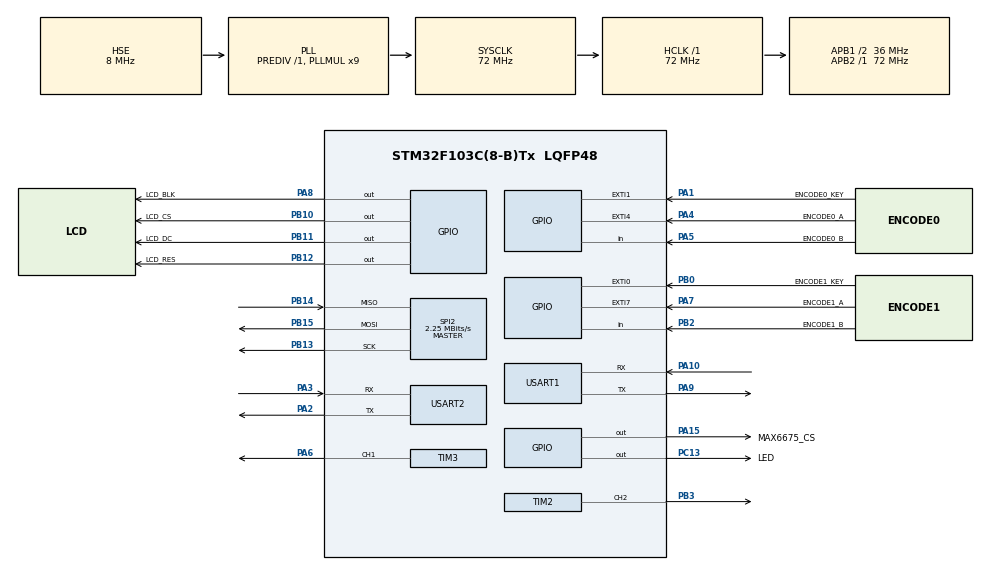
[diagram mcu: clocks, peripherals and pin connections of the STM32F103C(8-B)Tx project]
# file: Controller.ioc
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Dma.Request0=SPI2_RX
Dma.Request1=SPI2_TX
Dma.Request2=USART2_RX
Dma.Request3=USART2_TX
Dma.SPI2_RX.0.Direction=DMA_PERIPH_TO_MEMORY
Dma.SPI2_RX.0.Instance=DMA1_Channel4
Dma.SPI2_RX.0.MemDataAlignment=DMA_MDATAALIGN_BYTE
Dma.SPI2_RX.0.MemInc=DMA_MINC_ENABLE
Dma.SPI2_RX.0.Mode=DMA_NORMAL
Dma.SPI2_RX.0.PeriphDataAlignment=DMA_PDATAALIGN_BYTE
Dma.SPI2_RX.0.PeriphInc=DMA_PINC_DISABLE
Dma.SPI2_RX.0.Priority=DMA_PRIORITY_LOW
Dma.SPI2_TX.1.Direction=DMA_MEMORY_TO_PERIPH
Dma.SPI2_TX.1.Instance=DMA1_Channel5
Dma.SPI2_TX.1.MemDataAlignment=DMA_MDATAALIGN_BYTE
Dma.SPI2_TX.1.MemInc=DMA_MINC_ENABLE
Dma.SPI2_TX.1.Mode=DMA_NORMAL
Dma.SPI2_TX.1.PeriphDataAlignment=DMA_PDATAALIGN_BYTE
Dma.SPI2_TX.1.PeriphInc=DMA_PINC_DISABLE
Dma.SPI2_TX.1.Priority=DMA_PRIORITY_LOW
Dma.USART2_RX.2.Direction=DMA_PERIPH_TO_MEMORY
Dma.USART2_RX.2.Instance=DMA1_Channel6
Dma.USART2_RX.2.MemDataAlignment=DMA_MDATAALIGN_BYTE
Dma.USART2_RX.2.MemInc=DMA_MINC_ENABLE
Dma.USART2_RX.2.Mode=DMA_NORMAL
Dma.USART2_RX.2.PeriphDataAlignment=DMA_PDATAALIGN_BYTE
Dma.USART2_RX.2.PeriphInc=DMA_PINC_DISABLE
Dma.USART2_RX.2.Priority=DMA_PRIORITY_LOW
Dma.USART2_TX.3.Direction=DMA_MEMORY_TO_PERIPH
Dma.USART2_TX.3.Instance=DMA1_Channel7
Dma.USART2_TX.3.MemDataAlignment=DMA_MDATAALIGN_BYTE
Dma.USART2_TX.3.MemInc=DMA_MINC_ENABLE
Dma.USART2_TX.3.Mode=DMA_NORMAL
Dma.USART2_TX.3.PeriphDataAlignment=DMA_PDATAALIGN_BYTE
Dma.USART2_TX.3.PeriphInc=DMA_PINC_DISABLE
Dma.USART2_TX.3.Priority=DMA_PRIORITY_LOW
Mcu.Family=STM32F1
Mcu.Name=STM32F103C(8-B)Tx
Mcu.Package=LQFP48
NVIC.DMA1_Channel4_IRQn=true\:0\:0\:false\:false\:true\:false\:true\:true
NVIC.DMA1_Channel5_IRQn=true\:0\:0\:false\:false\:true\:false\:true\:true
NVIC.DMA1_Channel6_IRQn=true\:0\:0\:false\:false\:true\:false\:true\:true
NVIC.DMA1_Channel7_IRQn=true\:0\:0\:false\:false\:true\:false\:true\:true
NVIC.EXTI0_IRQn=true\:0\:0\:false\:false\:true\:true\:true\:true
NVIC.EXTI1_IRQn=true\:0\:0\:false\:false\:true\:true\:true\:true
NVIC.EXTI4_IRQn=true\:0\:0\:false\:false\:true\:true\:true\:true
NVIC.PriorityGroup=NVIC_PRIORITYGROUP_4
NVIC.SPI2_IRQn=true\:0\:0\:false\:false\:true\:true\:true\:true
NVIC.TIM1_UP_IRQn=true\:0\:0\:false\:false\:true\:true\:true\:true
NVIC.TIM2_IRQn=true\:0\:0\:false\:false\:true\:true\:true\:true
NVIC.TIM3_IRQn=true\:0\:0\:false\:false\:true\:true\:true\:true
NVIC.USART1_IRQn=true\:0\:0\:false\:false\:true\:true\:true\:true
NVIC.USART2_IRQn=true\:0\:0\:false\:false\:true\:true\:true\:true
PA1.GPIO_Label=ENCODE0_KEY
PA1.GPIO_ModeDefaultEXTI=GPIO_MODE_IT_RISING_FALLING
PA1.GPIO_PuPd=GPIO_PULLUP
PA1.Signal=GPXTI1
PA10.Mode=Asynchronous
PA10.Signal=USART1_RX
PA13.Mode=Serial_Wire
PA13.Signal=SYS_JTMS-SWDIO
PA14.Mode=Serial_Wire
PA14.Signal=SYS_JTCK-SWCLK
PA15.GPIO_Label=MAX6675_CS
PA15.GPIO_PuPd=GPIO_PULLUP
PA15.Signal=GPIO_Output
PA2.Mode=Asynchronous
PA2.Signal=USART2_TX
PA3.Mode=Asynchronous
PA3.Signal=USART2_RX
PA4.GPIO_Label=ENCODE0_A
PA4.GPIO_ModeDefaultEXTI=GPIO_MODE_IT_RISING_FALLING
PA4.GPIO_PuPd=GPIO_PULLUP
PA4.Signal=GPXTI4
PA5.GPIO_Label=ENCODE0_B
PA5.GPIO_PuPd=GPIO_PULLUP
PA5.Signal=GPIO_Input
PA6.Signal=S_TIM3_CH1
PA7.GPIO_Label=ENCODE1_A
PA7.GPIO_ModeDefaultEXTI=GPIO_MODE_IT_RISING
PA7.GPIO_PuPd=GPIO_PULLUP
PA7.Signal=GPXTI7
PA8.GPIO_Label=LCD_BLK
PA8.GPIO_PuPd=GPIO_PULLUP
PA8.Signal=GPIO_Output
PA9.Mode=Asynchronous
PA9.Signal=USART1_TX
PB0.GPIO_Label=ENCODE1_KEY
PB0.GPIO_ModeDefaultEXTI=GPIO_MODE_IT_RISING_FALLING
PB0.GPIO_PuPd=GPIO_PULLUP
PB0.Signal=GPXTI0
PB10.GPIO_Label=LCD_CS
PB10.GPIO_PuPd=GPIO_PULLUP
PB10.Signal=GPIO_Output
PB11.GPIO_Label=LCD_DC
PB11.GPIO_PuPd=GPIO_PULLUP
PB11.Signal=GPIO_Output
PB12.GPIO_Label=LCD_RES
PB12.GPIO_PuPd=GPIO_PULLUP
PB12.Signal=GPIO_Output
PB13.Mode=Full_Duplex_Master
PB13.Signal=SPI2_SCK
PB14.Mode=Full_Duplex_Master
PB14.Signal=SPI2_MISO
PB15.Mode=Full_Duplex_Master
PB15.Signal=SPI2_MOSI
PB2.GPIO_Label=ENCODE1_B
PB2.GPIO_PuPd=GPIO_PULLUP
PB2.Signal=GPIO_Input
PB3.Signal=S_TIM2_CH2
PC13-TAMPER-RTC.GPIO_Label=LED
PC13-TAMPER-RTC.GPIO_PuPd=GPIO_PULLDOWN
PC13-TAMPER-RTC.Signal=GPIO_Output
PD0-OSC_IN.Mode=HSE-External-Oscillator
PD0-OSC_IN.Signal=RCC_OSC_IN
PD1-OSC_OUT.Mode=HSE-External-Oscillator
PD1-OSC_OUT.Signal=RCC_OSC_OUT
ProjectManager.HeapSize=0x200
ProjectManager.StackSize=0x400
ProjectManager.TargetToolchain=MDK-ARM V5
RCC.AHBFreq_Value=72000000
RCC.APB1CLKDivider=RCC_HCLK_DIV2
RCC.APB1Freq_Value=36000000
RCC.APB1TimFreq_Value=72000000
RCC.APB2Freq_Value=72000000
RCC.APB2TimFreq_Value=72000000
RCC.HCLKFreq_Value=72000000
RCC.PLLMUL=RCC_PLL_MUL9
RCC.PLLSourceVirtual=RCC_PLLSOURCE_HSE
RCC.SYSCLKFreq_VALUE=72000000
RCC.SYSCLKSource=RCC_SYSCLKSOURCE_PLLCLK
RCC.USBFreq_Value=72000000
SH.S_TIM2_CH2.0=TIM2_CH2,PWM Generation2 CH2
SH.S_TIM3_CH1.0=TIM3_CH1,PWM Generation1 CH1
SPI2.BaudRatePrescaler=SPI_BAUDRATEPRESCALER_16
SPI2.CalculateBaudRate=2.25 MBits/s
SPI2.Direction=SPI_DIRECTION_2LINES
SPI2.Mode=SPI_MODE_MASTER
SPI2.VirtualType=VM_MASTER
TIM1.AutoReloadPreload=TIM_AUTORELOAD_PRELOAD_ENABLE
TIM1.Period=499
TIM1.Prescaler=7199
TIM2.AutoReloadPreload=TIM_AUTORELOAD_PRELOAD_ENABLE
TIM2.Channel-PWM\ Generation2\ CH2=TIM_CHANNEL_2
TIM2.Period=99
TIM2.Prescaler=36-1
TIM3.AutoReloadPreload=TIM_AUTORELOAD_PRELOAD_ENABLE
TIM3.Channel-PWM\ Generation1\ CH1=TIM_CHANNEL_1
TIM3.Period=100-1
TIM3.Prescaler=36-1
USART1.VirtualMode=VM_ASYNC
USART2.VirtualMode=VM_ASYNC
VP_TIM1_VS_ClockSourceINT.Mode=Internal
VP_TIM2_VS_ClockSourceINT.Mode=Internal
VP_TIM3_VS_ClockSourceINT.Mode=Internal
board=custom

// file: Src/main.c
/* USER CODE BEGIN Header */
/**
  ******************************************************************************
  * @file           : main.c
  * @brief          : Main program body
  ******************************************************************************
  * @attention
  *
  * Copyright (c) 2026 STMicroelectronics.
  * All rights reserved.
  *
  * This software is licensed under terms that can be found in the LICENSE file
  * in the root directory of this software component.
  * If no LICENSE file comes with this software, it is provided AS-IS.
  *
  ******************************************************************************
  */
/* USER CODE END Header */
#include "main.h"
#include "dma.h"
#include "spi.h"
#include "tim.h"
#include "usart.h"
#include "gpio.h"

/* USER CODE BEGIN Includes */
#include "System/Application.h"
#include "stdio.h"
/* USER CODE END Includes */

void SystemClock_Config(void);

int main(void)
{

  /* MCU Configuration--------------------------------------------------------*/

  /* Reset of all peripherals, Initializes the Flash interface and the Systick. */
  HAL_Init();

  /* Configure the system clock */
  SystemClock_Config();

  /* Initialize all configured peripherals */
  MX_GPIO_Init();
  MX_DMA_Init();
  MX_SPI2_Init();
  MX_TIM1_Init();
  MX_TIM2_Init();
  MX_USART1_UART_Init();
  MX_USART2_UART_Init();
  MX_TIM3_Init();
  /* USER CODE BEGIN 2 */
  HAL_GPIO_WritePin(LED_GPIO_Port,LED_Pin,GPIO_PIN_SET);
  Sys_Init();
  HAL_GPIO_WritePin(LED_GPIO_Port,LED_Pin,GPIO_PIN_RESET);
  /* USER CODE END 2 */

  /* Infinite loop */
  while (1)
  {

    /* USER CODE BEGIN 3 */
    Sys_Task();

  }
  /* USER CODE END 3 */
}

void SystemClock_Config(void)
{
  RCC_OscInitTypeDef RCC_OscInitStruct = {0};
  RCC_ClkInitTypeDef RCC_ClkInitStruct = {0};

  /** Initializes the RCC Oscillators according to the specified parameters
  * in the RCC_OscInitTypeDef structure.
  */
  RCC_OscInitStruct.OscillatorType = RCC_OSCILLATORTYPE_HSE;
  RCC_OscInitStruct.HSEState = RCC_HSE_ON;
  RCC_OscInitStruct.HSEPredivValue = RCC_HSE_PREDIV_DIV1;
  RCC_OscInitStruct.HSIState = RCC_HSI_ON;
  RCC_OscInitStruct.PLL.PLLState = RCC_PLL_ON;
  RCC_OscInitStruct.PLL.PLLSource = RCC_PLLSOURCE_HSE;
  RCC_OscInitStruct.PLL.PLLMUL = RCC_PLL_MUL9;
  if (HAL_RCC_OscConfig(&RCC_OscInitStruct) != HAL_OK)
  {
    Error_Handler();
  }

  /** Initializes the CPU, AHB and APB buses clocks
  */
  RCC_ClkInitStruct.ClockType = RCC_CLOCKTYPE_HCLK|RCC_CLOCKTYPE_SYSCLK
                              |RCC_CLOCKTYPE_PCLK1|RCC_CLOCKTYPE_PCLK2;
  RCC_ClkInitStruct.SYSCLKSource = RCC_SYSCLKSOURCE_PLLCLK;
  RCC_ClkInitStruct.AHBCLKDivider = RCC_SYSCLK_DIV1;
  RCC_ClkInitStruct.APB1CLKDivider = RCC_HCLK_DIV2;
  RCC_ClkInitStruct.APB2CLKDivider = RCC_HCLK_DIV1;

  if (HAL_RCC_ClockConfig(&RCC_ClkInitStruct, FLASH_LATENCY_2) != HAL_OK)
  {
    Error_Handler();
  }
}

void Error_Handler(void)
{
  __disable_irq();
  while (1)
  {
  }
}
